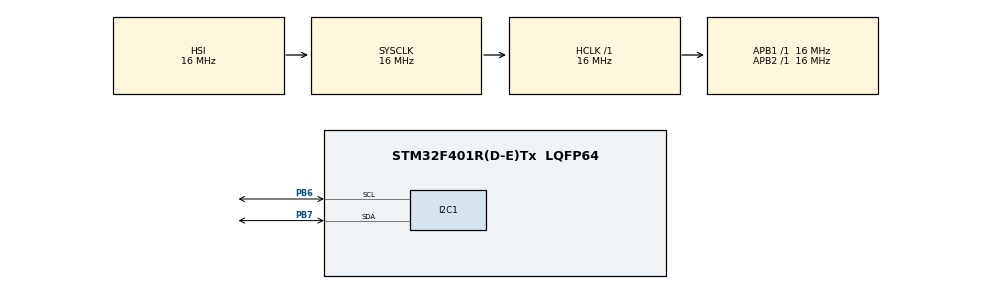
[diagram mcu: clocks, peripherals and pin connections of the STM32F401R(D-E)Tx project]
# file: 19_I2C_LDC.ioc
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Mcu.Family=STM32F4
Mcu.Name=STM32F401R(D-E)Tx
Mcu.Package=LQFP64
NVIC.PriorityGroup=NVIC_PRIORITYGROUP_4
PA13.Mode=Serial_Wire
PA13.Signal=SYS_JTMS-SWDIO
PA14.Mode=Serial_Wire
PA14.Signal=SYS_JTCK-SWCLK
PB6.Mode=I2C
PB6.Signal=I2C1_SCL
PB7.Mode=I2C
PB7.Signal=I2C1_SDA
ProjectManager.HeapSize=0x200
ProjectManager.StackSize=0x400
ProjectManager.TargetToolchain=STM32CubeIDE
RCC.AHBFreq_Value=16000000
RCC.APB1Freq_Value=16000000
RCC.APB2Freq_Value=16000000
RCC.CortexFreq_Value=16000000
RCC.HSE_VALUE=25000000
RCC.HSI_VALUE=16000000
RCC.LSE_VALUE=32768
RCC.SYSCLKFreq_VALUE=16000000
RCC.VCOOutputFreq_Value=192000000
board=custom

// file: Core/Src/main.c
/* USER CODE BEGIN Header */
/**
  ******************************************************************************
  * @file           : main.c
  * @brief          : Main program body
  ******************************************************************************
  * @attention
  *
  * Copyright (c) 2023 STMicroelectronics.
  * All rights reserved.
  *
  * This software is licensed under terms that can be found in the LICENSE file
  * in the root directory of this software component.
  * If no LICENSE file comes with this software, it is provided AS-IS.
  *
  ******************************************************************************
  */
/* USER CODE END Header */
#include <lcd_i2c.h>
#include "main.h"
#include "i2c.h"
#include "gpio.h"

/* USER CODE BEGIN Includes */
#include <stdio.h>
/* USER CODE END Includes */

/* USER CODE BEGIN PV */
uint8_t contador = 0;
char str_cont[16];
/* USER CODE END PV */

void SystemClock_Config(void);

int main(void)
{

  /* MCU Configuration--------------------------------------------------------*/

  /* Reset of all peripherals, Initializes the Flash interface and the Systick. */
  HAL_Init();

  /* Configure the system clock */
  SystemClock_Config();

  /* Initialize all configured peripherals */
  MX_GPIO_Init();
  MX_I2C1_Init();
  /* USER CODE BEGIN 2 */
  LCD_I2C_INIT();
  LCD_I2C_SET_CURSOR(1,fila1);
  LCD_I2C_PRINT_CHAR('D');
  LCD_I2C_PRINT_CHAR('I');
  LCD_I2C_PRINT_CHAR('E');
  LCD_I2C_PRINT_CHAR('G');
  LCD_I2C_PRINT_CHAR('O');
  /*
  LCD_I2C_SET_CURSOR(2,fila2);
  LCD_I2C_PRINT_CHAR('S');
  LCD_I2C_PRINT_CHAR('T');
  LCD_I2C_PRINT_CHAR('M');
  LCD_I2C_PRINT_CHAR('3');
  LCD_I2C_PRINT_CHAR('2');
  */

  LCD_I2C_SET_CURSOR(2,fila2);
  LCD_I2C_PRINT_STRING("LCD PRUEBA");
  HAL_Delay(2000);
  LCD_I2C_Clear();
  LCD_I2C_CursorOff();
  LCD_I2C_SET_CURSOR(0, fila1);
  LCD_I2C_PRINT_STRING("Contador: ");
  /* USER CODE END 2 */

  /* Infinite loop */
  /* USER CODE BEGIN WHILE */
  while (1)
  {

	  for(contador= 0 ; contador<256; contador++){
		  LCD_I2C_SET_CURSOR(0, fila2);
		  sprintf(str_cont,"%d",contador);
		  LCD_I2C_PRINT_STRING(str_cont);
		  HAL_Delay(100);
	  }
	  LCD_I2C_Clear();
	  /* USER CODE END WHILE */

  }
}

void SystemClock_Config(void)
{
  RCC_OscInitTypeDef RCC_OscInitStruct = {0};
  RCC_ClkInitTypeDef RCC_ClkInitStruct = {0};

  /** Configure the main internal regulator output voltage
  */
  __HAL_RCC_PWR_CLK_ENABLE();
  __HAL_PWR_VOLTAGESCALING_CONFIG(PWR_REGULATOR_VOLTAGE_SCALE2);

  /** Initializes the RCC Oscillators according to the specified parameters
  * in the RCC_OscInitTypeDef structure.
  */
  RCC_OscInitStruct.OscillatorType = RCC_OSCILLATORTYPE_HSI;
  RCC_OscInitStruct.HSIState = RCC_HSI_ON;
  RCC_OscInitStruct.HSICalibrationValue = RCC_HSICALIBRATION_DEFAULT;
  RCC_OscInitStruct.PLL.PLLState = RCC_PLL_NONE;
  if (HAL_RCC_OscConfig(&RCC_OscInitStruct) != HAL_OK)
  {
    Error_Handler();
  }

  /** Initializes the CPU, AHB and APB buses clocks
  */
  RCC_ClkInitStruct.ClockType = RCC_CLOCKTYPE_HCLK|RCC_CLOCKTYPE_SYSCLK
                              |RCC_CLOCKTYPE_PCLK1|RCC_CLOCKTYPE_PCLK2;
  RCC_ClkInitStruct.SYSCLKSource = RCC_SYSCLKSOURCE_HSI;
  RCC_ClkInitStruct.AHBCLKDivider = RCC_SYSCLK_DIV1;
  RCC_ClkInitStruct.APB1CLKDivider = RCC_HCLK_DIV1;
  RCC_ClkInitStruct.APB2CLKDivider = RCC_HCLK_DIV1;

  if (HAL_RCC_ClockConfig(&RCC_ClkInitStruct, FLASH_LATENCY_0) != HAL_OK)
  {
    Error_Handler();
  }
}

void Error_Handler(void)
{
  __disable_irq();
  while (1)
  {
  }
}
